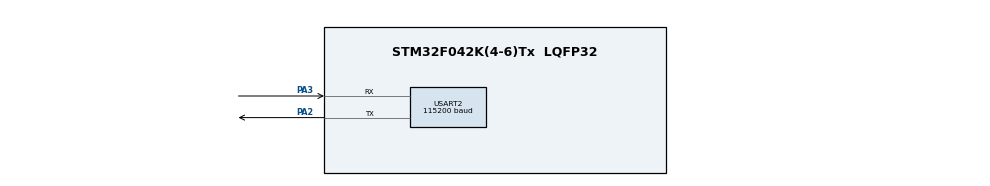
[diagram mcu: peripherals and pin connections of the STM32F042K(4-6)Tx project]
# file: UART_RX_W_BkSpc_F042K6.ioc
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Mcu.Family=STM32F0
Mcu.Name=STM32F042K(4-6)Tx
Mcu.Package=LQFP32
NVIC.USART2_IRQn=true\:0\:0\:false\:false\:true\:true\:true
PA2.Mode=Asynchronous
PA2.Signal=USART2_TX
PA3.Mode=Asynchronous
PA3.Signal=USART2_RX
ProjectManager.HeapSize=0x200
ProjectManager.StackSize=0x400
ProjectManager.TargetToolchain=STM32CubeIDE
USART2.BaudRate=115200
USART2.VirtualMode-Asynchronous=VM_ASYNC
board=custom

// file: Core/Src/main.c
/* USER CODE BEGIN Header */
/**
 ******************************************************************************
 * @file           : main.c
 * @brief          : Main program body
 ******************************************************************************
 * @attention
 *
 * <h2><center>&copy; Copyright (c) 2021 STMicroelectronics.
 * All rights reserved.</center></h2>
 *
 * This software component is licensed by ST under BSD 3-Clause license,
 * the "License"; You may not use this file except in compliance with the
 * License. You may obtain a copy of the License at:
 *                        opensource.org/licenses/BSD-3-Clause
 *
 ******************************************************************************
 */
/* USER CODE END Header */
#include "main.h"

/* USER CODE BEGIN Includes */
#include <string.h>
#include <stdio.h>
#include <stdint.h>
#include <stdarg.h>
#include <stdlib.h>
/* USER CODE END Includes */

/* USER CODE BEGIN PD */
#define UART_BUFF_SIZE 128	//at most 512 characters processed
/* USER CODE END PD */

UART_HandleTypeDef huart2;

/* USER CODE BEGIN PV */
char RXBuffer[UART_BUFF_SIZE] = { 0 };
char TXBuffer[UART_BUFF_SIZE] = { 0 };
uint8_t recvByte[1] = { 0 };
uint8_t UART_RX_Complete = RESET;
/* USER CODE END PV */

void SystemClock_Config(void);
static void MX_GPIO_Init(void);
static void MX_USART2_UART_Init(void);
/* USER CODE BEGIN PFP */
void HAL_UART_RxCpltCallback(UART_HandleTypeDef *huart); //UART rx int callback

void printMsg(char *format, ...); //func to print string to termial - printf substitute
/* USER CODE END PFP */

int main(void) {

	/* MCU Configuration--------------------------------------------------------*/

	/* Reset of all peripherals, Initializes the Flash interface and the Systick. */
	HAL_Init();

	/* Configure the system clock */
	SystemClock_Config();

	/* USER CODE BEGIN SysInit */
	__HAL_RCC_GPIOB_CLK_ENABLE();
	GPIO_InitTypeDef gpioInitStruct = {0};
	gpioInitStruct.Pin = GPIO_PIN_3;
	gpioInitStruct.Mode = GPIO_MODE_OUTPUT_PP;
	gpioInitStruct.Pull = GPIO_NOPULL;
	gpioInitStruct.Speed = GPIO_SPEED_FREQ_HIGH;
	HAL_GPIO_Init(GPIOB, &gpioInitStruct);
	HAL_GPIO_WritePin(GPIOB, GPIO_PIN_3, GPIO_PIN_SET);

	/* USER CODE END SysInit */

	/* Initialize all configured peripherals */
	MX_GPIO_Init();
	MX_USART2_UART_Init();
	/* USER CODE BEGIN 2 */
	printMsg("Built on: %s %s\r\n", __DATE__, __TIME__);
	printMsg("Engineer: Aditya Sehgal\n");
	/* USER CODE END 2 */

	/* Infinite loop */
	/* USER CODE BEGIN WHILE */
	while (1) {
		HAL_UART_Receive_IT(&huart2, recvByte, 1);
		/* USER CODE END WHILE */

		/* USER CODE BEGIN 3 */
		if (UART_RX_Complete == SET) {
			UART_RX_Complete = RESET;
			printMsg(RXBuffer);
			memset(RXBuffer, 0, sizeof(RXBuffer));
		}

		if(HAL_GetTick() % 500 == 0)
			HAL_GPIO_TogglePin(GPIOB, GPIO_PIN_3);
	}
	/* USER CODE END 3 */
}

void SystemClock_Config(void) {
	RCC_OscInitTypeDef RCC_OscInitStruct = { 0 };
	RCC_ClkInitTypeDef RCC_ClkInitStruct = { 0 };

	/** Initializes the RCC Oscillators according to the specified parameters
	 * in the RCC_OscInitTypeDef structure.
	 */
	RCC_OscInitStruct.OscillatorType = RCC_OSCILLATORTYPE_HSI;
	RCC_OscInitStruct.HSIState = RCC_HSI_ON;
	RCC_OscInitStruct.HSICalibrationValue = RCC_HSICALIBRATION_DEFAULT;
	RCC_OscInitStruct.PLL.PLLState = RCC_PLL_NONE;
	if (HAL_RCC_OscConfig(&RCC_OscInitStruct) != HAL_OK) {
		Error_Handler();
	}
	/** Initializes the CPU, AHB and APB buses clocks
	 */
	RCC_ClkInitStruct.ClockType = RCC_CLOCKTYPE_HCLK | RCC_CLOCKTYPE_SYSCLK
			| RCC_CLOCKTYPE_PCLK1;
	RCC_ClkInitStruct.SYSCLKSource = RCC_SYSCLKSOURCE_HSI;
	RCC_ClkInitStruct.AHBCLKDivider = RCC_SYSCLK_DIV1;
	RCC_ClkInitStruct.APB1CLKDivider = RCC_HCLK_DIV1;

	if (HAL_RCC_ClockConfig(&RCC_ClkInitStruct, FLASH_LATENCY_0) != HAL_OK) {
		Error_Handler();
	}
}

static void MX_USART2_UART_Init(void) {

	huart2.Instance = USART2;
	huart2.Init.BaudRate = 115200;
	huart2.Init.WordLength = UART_WORDLENGTH_8B;
	huart2.Init.StopBits = UART_STOPBITS_1;
	huart2.Init.Parity = UART_PARITY_NONE;
	huart2.Init.Mode = UART_MODE_TX_RX;
	huart2.Init.HwFlowCtl = UART_HWCONTROL_NONE;
	huart2.Init.OverSampling = UART_OVERSAMPLING_16;
	huart2.Init.OneBitSampling = UART_ONE_BIT_SAMPLE_DISABLE;
	huart2.AdvancedInit.AdvFeatureInit = UART_ADVFEATURE_NO_INIT;
	if (HAL_UART_Init(&huart2) != HAL_OK) {
		Error_Handler();
	}

}

static void MX_GPIO_Init(void) {

	/* GPIO Ports Clock Enable */
	__HAL_RCC_GPIOA_CLK_ENABLE();

}

/* USER CODE BEGIN 4 */
void HAL_UART_RxCpltCallback(UART_HandleTypeDef *huart) {	//UART INT callback
	//this strips user input of new line char
	if ((recvByte[0] == '\n')) {
		UART_RX_Complete = SET;
	} else if (recvByte[0] == '\r') {
		// do nothing - remove carriage return
	} else {
		strncat(RXBuffer, (char*) recvByte, 1);	//concatenate char into string byte by byte
	}
}

void printMsg(char *format, ...) {
	char str[80];

	/*Extract the the argument list using VA apis */
	va_list args;
	va_start(args, format);
	vsprintf(str, format, args);
	HAL_UART_Transmit(&huart2, (uint8_t*) str, strlen(str), HAL_MAX_DELAY);
	va_end(args);
}
/* USER CODE END 4 */

void Error_Handler(void) {
	__disable_irq();
	while (1) {
	}
}

/************************ (C) COPYRIGHT STMicroelectronics *****END OF FILE****/
